# GD32F4xx register map
File version: 1.0
CPU: CM4 r0p1, little endian, MPU, FPU, 4 interrupt priority bits
Registers are 32-bit, read-write, reset 0x0 unless marked. A register's access mark holds for its fields unless they carry their own. Offsets are from the block's base; [hi:lo] are bit positions; {n}, {i} and the like mark numbered series.

## ENET_PTP — Ethernet: Precision time protocol
Base 0x40028700
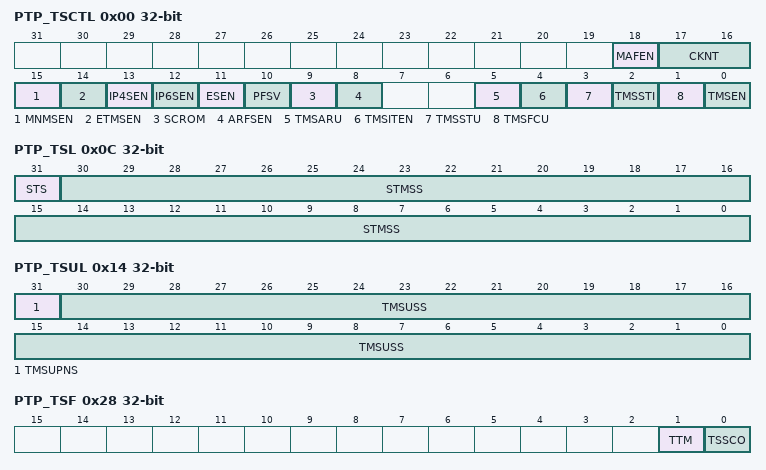
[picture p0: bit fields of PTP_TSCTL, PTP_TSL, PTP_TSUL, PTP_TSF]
0x00 PTP_TSCTL — Ethernet PTP time stamp control register (PTP_TSCTL)
  [18] MAFEN — MAC address filter enable for PTP frame
  [17:16] CKNT — Clock node type for time stamp
  [15] MNMSEN — Received master node message snapshot enable
  [14] ETMSEN — Received event type message snapshot enable
  [13] IP4SEN — Received IPv4 snapshot enable
  [12] IP6SEN — Received IPv6 snapshot enable
  [11] ESEN — Received Ethernet snapshot enable
  [10] PFSV — PTP frame snooping version
  [9] SCROM — Subsecond counter rollover mode
  [8] ARFSEN — All received frames snapshot enable
  [5] TMSARU — Time stamp addend register update
  [4] TMSITEN — Time stamp interrupt trigger enable
  [3] TMSSTU — Time stamp system time update
  [2] TMSSTI — Time stamp system time initialize
  [1] TMSFCU — Time stamp fine or coarse update
  [0] TMSEN — Time stamp enable
0x04 PTP_SSINC — Ethernet PTP subsecond increment register
  [7:0] STMSSI — System time subsecond increment
0x08 PTP_TSH ro — Ethernet PTP time stamp high register
  [31:0] STMS — System time second
0x0C PTP_TSL ro — Ethernet PTP time stamp low register (PTP_TSL)
  [31] STS — System time sign
  [30:0] STMSS — System time subseconds
0x10 PTP_TSUH — Ethernet PTP time stamp high update register
  [31:0] TMSUS — Time stamp update second
0x14 PTP_TSUL — Ethernet PTP time stamp low update register (PTP_TSUL)
  [31] TMSUPNS — Time stamp update positive or negative sign
  [30:0] TMSUSS — Time stamp update subseconds
0x18 PTP_TSADDEND — Ethernet PTP time stamp addend register
  [31:0] TMSA — Time stamp addend
0x1C PTP_ETH — Ethernet PTP expected time high register
  [31:0] ETSH — Expected time stamp high
0x20 PTP_ETL — Ethernet PTP expected time low register
  [31:0] ETSL — Expected time stamp low
0x28 PTP_TSF ro — Ethernet PTP time stamp flag register
  [1] TTM — Target time match
  [0] TSSCO — Timestamp second counter overflow
0x2C PTP_PPSCTL — Ethernet PTP PPS control register
  [3:0] PPSOFC — PPS output frequency configure

## EXTI — External interrupt/event controller
Base 0x40013C00
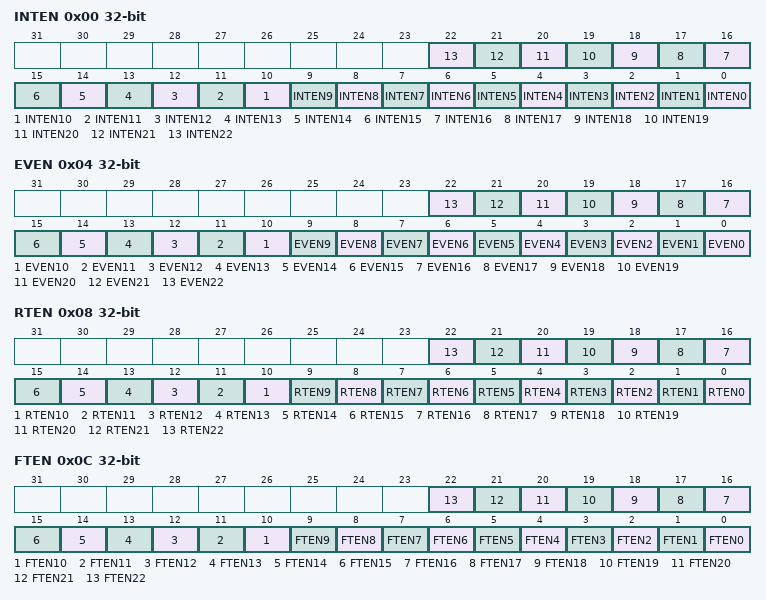
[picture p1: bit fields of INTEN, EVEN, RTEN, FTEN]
0x00 INTEN — Interrupt enable register (EXTI_INTEN)
  [n] INTEN{n} (n=0..22) — Enable Interrupt on line {n}
0x04 EVEN — Event enable register (EXTI_EVEN)
  [n] EVEN{n} (n=0..22) — Enable Event on line {n}
0x08 RTEN — Rising Edge Trigger Enable register (EXTI_RTEN)
  [n] RTEN{n} (n=0..22) — Rising edge trigger enable of line {n}
0x0C FTEN — Falling Egde Trigger Enable register (EXTI_FTEN)
  [n] FTEN{n} (n=0..22) — Falling edge trigger enable of line {n}
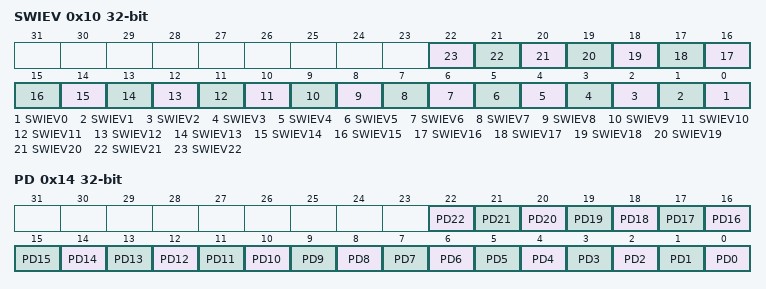
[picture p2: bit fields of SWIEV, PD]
0x10 SWIEV — Software interrupt event register (EXTI_SWIEV)
  [n] SWIEV{n} (n=0..22) — Interrupt/Event software trigger on line {n}
0x14 PD — Pending register (EXTI_PD)
  [n] PD{n} (n=0..22) — Interrupt pending status of line {n}

## FMC
Base 0x40023C00
0x00 WS — wait state counter register
  [3:0] WSCNT
0x04 KEY wo — Unlock key register
  [31:0] KEY — FMC_CTL unlock register
0x08 OBKEY wo — Option byte unlock key register
  [31:0] OBKEY — FMC_ OBCTL0 option byte operation unlock register
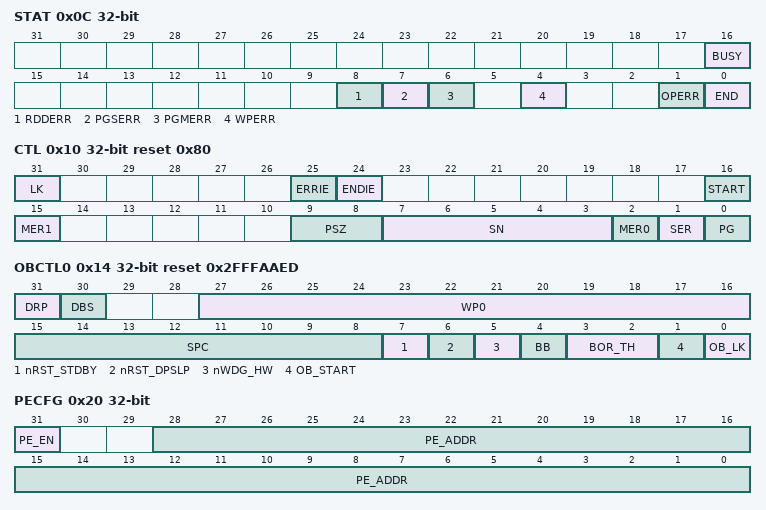
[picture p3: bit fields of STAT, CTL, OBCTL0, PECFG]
0x0C STAT access per field — Status register
  [16] BUSY ro — The flash is busy bit
  [8] RDDERR rw — Read D-bus protection error flag bit
  [7] PGSERR rw — Program sequence error flag bit
  [6] PGMERR rw — Program size not match error flag bit
  [4] WPERR rw — Erase/Program protection error flag bit
  [1] OPERR rw — Flash operation error flag bit
  [0] END rw — End of operation flag bit
0x10 CTL reset 0x80 — Control register
  [31] LK — FMC_CTL lock bit
  [25] ERRIE — Error interrupt enable bit
  [24] ENDIE — End of operation interrupt enable bit
  [16] START — send erase command to FMC bit
  [15] MER1 — main flash mass erase for bank1command bit
  [9:8] PSZ — Program size bit
  [7:3] SN — Select which sector number to be erased.
  [2] MER0 — main flash mass erase for bank0 command bit
  [1] SER — main flash sector erase command bit
  [0] PG — main flash program command bit
0x14 OBCTL0 reset 0x2FFFAAED — Option byte control register 0
  [31] DRP — D-bus read protection bit
  [30] DBS — Double banks or single bank selection when flash size is 1M
  [27:16] WP0 — Erase/program protection of each sector when DRP is 0
  [15:8] SPC — option byte Security Protection code
  [7] nRST_STDBY — option byte standby reset value
  [6] nRST_DPSLP — option byte deepsleep reset value
  [5] nWDG_HW — option byte watchdog value
  [4] BB — option byte boot bank value
  [3:2] BOR_TH — option byte BOR threshold value
  [1] OB_START — send option byte change command to FMC bit
  [0] OB_LK — FMC_OBCTL0 lock bit
0x18 OBCTL1 reset 0xFFF0000 — Option byte control register 1
  [27:16] WP1 — Erase/program protection of each sector when DRP is 0
0x20 PECFG — Page erase configuration register
  [31] PE_EN — The enable bit of page erase function
  [28:0] PE_ADDR — Page address (4KB alignment)
0x24 PEKEY wo — Unlock page erase key register
  [31:0] PE_KEY — FMC_PECFG unlock register
0xFC WSEN ro — Wait state enable register
  [0] WSEN — FMC wait state enable register
0x100 PID ro — Product ID register
  [31:0] PID — Product reserved ID code register
